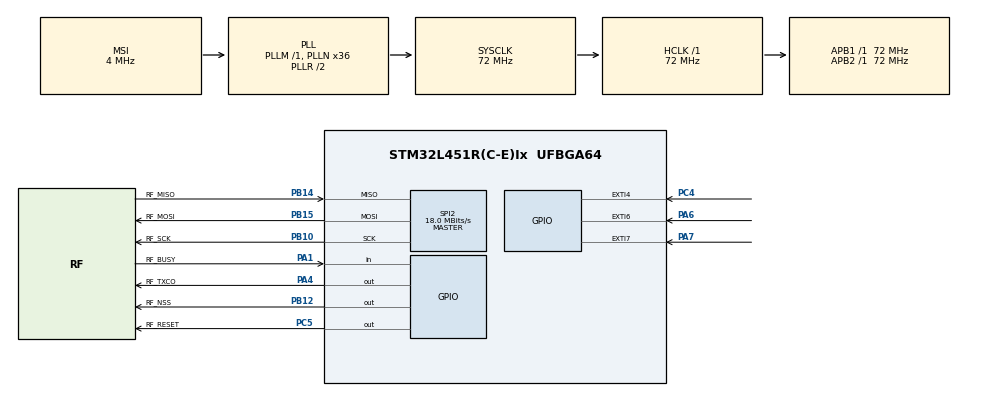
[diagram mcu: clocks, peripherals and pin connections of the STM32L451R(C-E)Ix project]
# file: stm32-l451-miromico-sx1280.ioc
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Mcu.Family=STM32L4
Dma.SPI2_RX.0.Instance=DMA1_Channel4
TIM2.Channel-Output\ Compare1\ No\ Output=TIM_CHANNEL_1
RCC.CortexFreq_Value=72000000
NVIC.DMA1_Channel5_IRQn=true\:0\:0\:false\:false\:true\:false\:true
SPI2.VirtualType=VM_MASTER
PB10.Mode=Full_Duplex_Master
PB14.GPIO_Label=RF_MISO
Dma.SPI2_TX.1.PeriphInc=DMA_PINC_DISABLE
PC15-OSC32_OUT\ (PC15).Mode=LSE-External-Oscillator
PB15.Signal=SPI2_MOSI
RCC.SYSCLKSource=RCC_SYSCLKSOURCE_PLLCLK
ProjectManager.StackSize=0x400
PC14-OSC32_IN\ (PC14).Mode=LSE-External-Oscillator
RCC.HCLKFreq_Value=72000000
RCC.APB2TimFreq_Value=72000000
RCC.AHBFreq_Value=72000000
SPI2.BaudRatePrescaler=SPI_BAUDRATEPRESCALER_4
RCC.HSE_VALUE=8000000
VP_TIM2_VS_no_output1.Mode=Output Compare1 No Output
PB12.GPIO_Label=RF_NSS
PB14.Mode=Full_Duplex_Master
NVIC.TIM2_IRQn=true\:0\:0\:false\:false\:true\:true\:true
SPI2.CalculateBaudRate=18.0 MBits/s
Dma.SPI2_RX.0.MemDataAlignment=DMA_MDATAALIGN_BYTE
NVIC.SPI2_IRQn=true\:0\:0\:false\:false\:true\:true\:true
Dma.SPI2_RX.0.MemInc=DMA_MINC_ENABLE
Mcu.Package=UFBGA64
TIM2.Prescaler=71
PA6.Signal=GPXTI6
Dma.SPI2_TX.1.Mode=DMA_NORMAL
SPI2.Mode=SPI_MODE_MASTER
VP_LPTIM1_VS_LPTIM_counterModeInternalClock.Mode=Counts__internal_clock_event_00
Dma.SPI2_TX.1.Instance=DMA1_Channel5
Dma.Request1=SPI2_TX
RCC.APB1TimFreq_Value=72000000
SPI2.Direction=SPI_DIRECTION_2LINES
PC5.Signal=GPIO_Output
Dma.SPI2_RX.0.Direction=DMA_PERIPH_TO_MEMORY
NVIC.DMA1_Channel4_IRQn=true\:0\:0\:false\:false\:true\:false\:true
Dma.Request0=SPI2_RX
PA4.GPIO_Label=RF_TXCO
RCC.HSI48_VALUE=48000000
RCC.MSI_VALUE=4000000
Dma.SPI2_TX.1.MemInc=DMA_MINC_ENABLE
NVIC.EXTI4_IRQn=true\:0\:0\:false\:false\:true\:true\:true
Dma.SPI2_RX.0.Mode=DMA_NORMAL
PC4.Signal=GPXTI4
PC15-OSC32_OUT\ (PC15).Signal=RCC_OSC32_OUT
Dma.SPI2_RX.0.PeriphDataAlignment=DMA_PDATAALIGN_BYTE
ProjectManager.TargetToolchain=Makefile
PB10.GPIO_Label=RF_SCK
RCC.LPTIM1CLockSelection=RCC_LPTIM1CLKSOURCE_LSE
PA1.Signal=GPIO_Input
PB12.GPIO_Speed=GPIO_SPEED_FREQ_VERY_HIGH
PB10.Signal=SPI2_SCK
PB14.Signal=SPI2_MISO
board=custom
Dma.SPI2_TX.1.Direction=DMA_MEMORY_TO_PERIPH
RCC.VCOOutputFreq_Value=144000000
PB15.Mode=Full_Duplex_Master
NVIC.LPTIM1_IRQn=true\:0\:0\:false\:false\:true\:true\:true
RCC.APB2Freq_Value=72000000
Dma.SPI2_TX.1.PeriphDataAlignment=DMA_PDATAALIGN_BYTE
PB15.GPIO_Label=RF_MOSI
VP_TIM2_VS_ClockSourceINT.Mode=Internal
Dma.SPI2_TX.1.Priority=DMA_PRIORITY_LOW
RCC.ADCFreq_Value=16000000
PA1.GPIO_Label=RF_BUSY
TIM2.Period=0xffffffff
Dma.SPI2_RX.0.Priority=DMA_PRIORITY_LOW
Mcu.Name=STM32L451R(C-E)Ix
PA4.Signal=GPIO_Output
RCC.SYSCLKFreq_VALUE=72000000
PC5.GPIO_Label=RF_RESET
PC14-OSC32_IN\ (PC14).Signal=RCC_OSC32_IN
Dma.SPI2_RX.0.PeriphInc=DMA_PINC_DISABLE
NVIC.EXTI9_5_IRQn=true\:0\:0\:false\:false\:true\:true\:true
ProjectManager.HeapSize=0x200
RCC.HSI_VALUE=16000000
NVIC.PriorityGroup=NVIC_PRIORITYGROUP_4
RCC.PLLN=36
SPI2.DataSize=SPI_DATASIZE_8BIT
RCC.APB1Freq_Value=72000000
Dma.SPI2_TX.1.MemDataAlignment=DMA_MDATAALIGN_BYTE
PB12.Signal=GPIO_Output
PA7.Signal=GPXTI7

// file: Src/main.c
/* USER CODE BEGIN Header */
/**
  ******************************************************************************
  * @file           : main.c
  * @brief          : Main program body
  ******************************************************************************
  * @attention
  *
  * <h2><center>&copy; Copyright (c) 2020 STMicroelectronics.
  * All rights reserved.</center></h2>
  *
  * This software component is licensed by ST under BSD 3-Clause license,
  * the "License"; You may not use this file except in compliance with the
  * License. You may obtain a copy of the License at:
  *                        opensource.org/licenses/BSD-3-Clause
  *
  ******************************************************************************
  */
/* USER CODE END Header */

#include "main.h"

/* USER CODE BEGIN Includes */
#include "SEGGER_RTT.h"
#include <stdio.h>
#include "sx1280-hal.h"

/* USER CODE END Includes */

/* USER CODE BEGIN PM */
#define printf(format, ...) SEGGER_RTT_printf(0, format,  ## __VA_ARGS__)

/* USER CODE END PM */

LPTIM_HandleTypeDef hlptim1;

SPI_HandleTypeDef hspi2;
DMA_HandleTypeDef hdma_spi2_rx;
DMA_HandleTypeDef hdma_spi2_tx;

TIM_HandleTypeDef htim2;

void SystemClock_Config(void);
static void MX_GPIO_Init(void);
static void MX_DMA_Init(void);
static void MX_SPI2_Init(void);
static void MX_TIM2_Init(void);
static void MX_LPTIM1_Init(void);
/* USER CODE BEGIN PFP */
void btstack_port(void);

/* USER CODE END PFP */

int main(void)
{

  /* MCU Configuration--------------------------------------------------------*/

  /* Reset of all peripherals, Initializes the Flash interface and the Systick. */
  HAL_Init();

  /* Configure the system clock */
  SystemClock_Config();

  /* Initialize all configured peripherals */
  MX_GPIO_Init();
  MX_DMA_Init();
  MX_SPI2_Init();
  MX_TIM2_Init();
  MX_LPTIM1_Init();
  /* USER CODE BEGIN 2 */

  HAL_TIM_Base_Start(&htim2);
  // HAL_LPTIM_Counter_Start_IT same as HAL_LPTIM_Counter_Start but also enables IRQs
  HAL_LPTIM_Counter_Start_IT(&hlptim1, 0xffff);

  // Enable SX1280 Clock
  HAL_GPIO_WritePin(RF_TXCO_GPIO_Port, RF_TXCO_Pin, GPIO_PIN_SET);

  btstack_port();

  /* USER CODE END 2 */

  /* Infinite loop */
  /* USER CODE BEGIN WHILE */
  while (1)
  {
    // printf("[%06u] BUSY %u\n", hal_time_ms(), HAL_GPIO_ReadPin(RF_BUSY_GPIO_Port, RF_BUSY_Pin));
    /* USER CODE END WHILE */

  }
}

void SystemClock_Config(void)
{
  RCC_OscInitTypeDef RCC_OscInitStruct = {0};
  RCC_ClkInitTypeDef RCC_ClkInitStruct = {0};
  RCC_PeriphCLKInitTypeDef PeriphClkInit = {0};

  /** Configure LSE Drive Capability
  */
  HAL_PWR_EnableBkUpAccess();
  __HAL_RCC_LSEDRIVE_CONFIG(RCC_LSEDRIVE_LOW);
  /** Initializes the CPU, AHB and APB busses clocks
  */
  RCC_OscInitStruct.OscillatorType = RCC_OSCILLATORTYPE_LSE|RCC_OSCILLATORTYPE_MSI;
  RCC_OscInitStruct.LSEState = RCC_LSE_ON;
  RCC_OscInitStruct.MSIState = RCC_MSI_ON;
  RCC_OscInitStruct.MSICalibrationValue = 0;
  RCC_OscInitStruct.MSIClockRange = RCC_MSIRANGE_6;
  RCC_OscInitStruct.PLL.PLLState = RCC_PLL_ON;
  RCC_OscInitStruct.PLL.PLLSource = RCC_PLLSOURCE_MSI;
  RCC_OscInitStruct.PLL.PLLM = 1;
  RCC_OscInitStruct.PLL.PLLN = 36;
  RCC_OscInitStruct.PLL.PLLP = RCC_PLLP_DIV7;
  RCC_OscInitStruct.PLL.PLLQ = RCC_PLLQ_DIV2;
  RCC_OscInitStruct.PLL.PLLR = RCC_PLLR_DIV2;
  if (HAL_RCC_OscConfig(&RCC_OscInitStruct) != HAL_OK)
  {
    Error_Handler();
  }
  /** Initializes the CPU, AHB and APB busses clocks
  */
  RCC_ClkInitStruct.ClockType = RCC_CLOCKTYPE_HCLK|RCC_CLOCKTYPE_SYSCLK
                              |RCC_CLOCKTYPE_PCLK1|RCC_CLOCKTYPE_PCLK2;
  RCC_ClkInitStruct.SYSCLKSource = RCC_SYSCLKSOURCE_PLLCLK;
  RCC_ClkInitStruct.AHBCLKDivider = RCC_SYSCLK_DIV1;
  RCC_ClkInitStruct.APB1CLKDivider = RCC_HCLK_DIV1;
  RCC_ClkInitStruct.APB2CLKDivider = RCC_HCLK_DIV1;

  if (HAL_RCC_ClockConfig(&RCC_ClkInitStruct, FLASH_LATENCY_4) != HAL_OK)
  {
    Error_Handler();
  }
  PeriphClkInit.PeriphClockSelection = RCC_PERIPHCLK_LPTIM1;
  PeriphClkInit.Lptim1ClockSelection = RCC_LPTIM1CLKSOURCE_LSE;
  if (HAL_RCCEx_PeriphCLKConfig(&PeriphClkInit) != HAL_OK)
  {
    Error_Handler();
  }
  /** Configure the main internal regulator output voltage
  */
  if (HAL_PWREx_ControlVoltageScaling(PWR_REGULATOR_VOLTAGE_SCALE1) != HAL_OK)
  {
    Error_Handler();
  }
  /** Enable MSI Auto calibration
  */
  HAL_RCCEx_EnableMSIPLLMode();
}

static void MX_LPTIM1_Init(void)
{

  hlptim1.Instance = LPTIM1;
  hlptim1.Init.Clock.Source = LPTIM_CLOCKSOURCE_APBCLOCK_LPOSC;
  hlptim1.Init.Clock.Prescaler = LPTIM_PRESCALER_DIV1;
  hlptim1.Init.Trigger.Source = LPTIM_TRIGSOURCE_SOFTWARE;
  hlptim1.Init.OutputPolarity = LPTIM_OUTPUTPOLARITY_HIGH;
  hlptim1.Init.UpdateMode = LPTIM_UPDATE_IMMEDIATE;
  hlptim1.Init.CounterSource = LPTIM_COUNTERSOURCE_INTERNAL;
  hlptim1.Init.Input1Source = LPTIM_INPUT1SOURCE_GPIO;
  hlptim1.Init.Input2Source = LPTIM_INPUT2SOURCE_GPIO;
  if (HAL_LPTIM_Init(&hlptim1) != HAL_OK)
  {
    Error_Handler();
  }

}

static void MX_SPI2_Init(void)
{

  /* SPI2 parameter configuration*/
  hspi2.Instance = SPI2;
  hspi2.Init.Mode = SPI_MODE_MASTER;
  hspi2.Init.Direction = SPI_DIRECTION_2LINES;
  hspi2.Init.DataSize = SPI_DATASIZE_8BIT;
  hspi2.Init.CLKPolarity = SPI_POLARITY_LOW;
  hspi2.Init.CLKPhase = SPI_PHASE_1EDGE;
  hspi2.Init.NSS = SPI_NSS_SOFT;
  hspi2.Init.BaudRatePrescaler = SPI_BAUDRATEPRESCALER_4;
  hspi2.Init.FirstBit = SPI_FIRSTBIT_MSB;
  hspi2.Init.TIMode = SPI_TIMODE_DISABLE;
  hspi2.Init.CRCCalculation = SPI_CRCCALCULATION_DISABLE;
  hspi2.Init.CRCPolynomial = 7;
  hspi2.Init.CRCLength = SPI_CRC_LENGTH_DATASIZE;
  hspi2.Init.NSSPMode = SPI_NSS_PULSE_ENABLE;
  if (HAL_SPI_Init(&hspi2) != HAL_OK)
  {
    Error_Handler();
  }

}

static void MX_TIM2_Init(void)
{

  TIM_ClockConfigTypeDef sClockSourceConfig = {0};
  TIM_MasterConfigTypeDef sMasterConfig = {0};
  TIM_OC_InitTypeDef sConfigOC = {0};

  htim2.Instance = TIM2;
  htim2.Init.Prescaler = 70;
  htim2.Init.CounterMode = TIM_COUNTERMODE_UP;
  htim2.Init.Period = 0xffffffff;
  htim2.Init.ClockDivision = TIM_CLOCKDIVISION_DIV1;
  htim2.Init.AutoReloadPreload = TIM_AUTORELOAD_PRELOAD_DISABLE;
  if (HAL_TIM_Base_Init(&htim2) != HAL_OK)
  {
    Error_Handler();
  }
  sClockSourceConfig.ClockSource = TIM_CLOCKSOURCE_INTERNAL;
  if (HAL_TIM_ConfigClockSource(&htim2, &sClockSourceConfig) != HAL_OK)
  {
    Error_Handler();
  }
  if (HAL_TIM_OC_Init(&htim2) != HAL_OK)
  {
    Error_Handler();
  }
  sMasterConfig.MasterOutputTrigger = TIM_TRGO_RESET;
  sMasterConfig.MasterSlaveMode = TIM_MASTERSLAVEMODE_DISABLE;
  if (HAL_TIMEx_MasterConfigSynchronization(&htim2, &sMasterConfig) != HAL_OK)
  {
    Error_Handler();
  }
  sConfigOC.OCMode = TIM_OCMODE_TIMING;
  sConfigOC.Pulse = 0;
  sConfigOC.OCPolarity = TIM_OCPOLARITY_HIGH;
  sConfigOC.OCFastMode = TIM_OCFAST_DISABLE;
  if (HAL_TIM_OC_ConfigChannel(&htim2, &sConfigOC, TIM_CHANNEL_1) != HAL_OK)
  {
    Error_Handler();
  }

}

static void MX_DMA_Init(void)
{

  /* DMA controller clock enable */
  __HAL_RCC_DMA1_CLK_ENABLE();

  /* DMA interrupt init */
  /* DMA1_Channel4_IRQn interrupt configuration */
  HAL_NVIC_SetPriority(DMA1_Channel4_IRQn, 0, 0);
  HAL_NVIC_EnableIRQ(DMA1_Channel4_IRQn);
  /* DMA1_Channel5_IRQn interrupt configuration */
  HAL_NVIC_SetPriority(DMA1_Channel5_IRQn, 0, 0);
  HAL_NVIC_EnableIRQ(DMA1_Channel5_IRQn);

}

static void MX_GPIO_Init(void)
{
  GPIO_InitTypeDef GPIO_InitStruct = {0};

  /* GPIO Ports Clock Enable */
  __HAL_RCC_GPIOC_CLK_ENABLE();
  __HAL_RCC_GPIOB_CLK_ENABLE();
  __HAL_RCC_GPIOA_CLK_ENABLE();

  /*Configure GPIO pin Output Level */
  HAL_GPIO_WritePin(RF_TXCO_GPIO_Port, RF_TXCO_Pin, GPIO_PIN_RESET);

  /*Configure GPIO pin Output Level */
  HAL_GPIO_WritePin(RF_RESET_GPIO_Port, RF_RESET_Pin, GPIO_PIN_RESET);

  /*Configure GPIO pin Output Level */
  HAL_GPIO_WritePin(RF_NSS_GPIO_Port, RF_NSS_Pin, GPIO_PIN_RESET);

  /*Configure GPIO pins : PA6 PA7 */
  GPIO_InitStruct.Pin = GPIO_PIN_6|GPIO_PIN_7;
  GPIO_InitStruct.Mode = GPIO_MODE_IT_RISING;
  GPIO_InitStruct.Pull = GPIO_NOPULL;
  HAL_GPIO_Init(GPIOA, &GPIO_InitStruct);

  /*Configure GPIO pin : RF_BUSY_Pin */
  GPIO_InitStruct.Pin = RF_BUSY_Pin;
  GPIO_InitStruct.Mode = GPIO_MODE_INPUT;
  GPIO_InitStruct.Pull = GPIO_NOPULL;
  HAL_GPIO_Init(RF_BUSY_GPIO_Port, &GPIO_InitStruct);

  /*Configure GPIO pin : RF_TXCO_Pin */
  GPIO_InitStruct.Pin = RF_TXCO_Pin;
  GPIO_InitStruct.Mode = GPIO_MODE_OUTPUT_PP;
  GPIO_InitStruct.Pull = GPIO_NOPULL;
  GPIO_InitStruct.Speed = GPIO_SPEED_FREQ_LOW;
  HAL_GPIO_Init(RF_TXCO_GPIO_Port, &GPIO_InitStruct);

  /*Configure GPIO pin : PC4 */
  GPIO_InitStruct.Pin = GPIO_PIN_4;
  GPIO_InitStruct.Mode = GPIO_MODE_IT_RISING;
  GPIO_InitStruct.Pull = GPIO_NOPULL;
  HAL_GPIO_Init(GPIOC, &GPIO_InitStruct);

  /*Configure GPIO pin : RF_RESET_Pin */
  GPIO_InitStruct.Pin = RF_RESET_Pin;
  GPIO_InitStruct.Mode = GPIO_MODE_OUTPUT_PP;
  GPIO_InitStruct.Pull = GPIO_NOPULL;
  GPIO_InitStruct.Speed = GPIO_SPEED_FREQ_LOW;
  HAL_GPIO_Init(RF_RESET_GPIO_Port, &GPIO_InitStruct);

  /*Configure GPIO pin : RF_NSS_Pin */
  GPIO_InitStruct.Pin = RF_NSS_Pin;
  GPIO_InitStruct.Mode = GPIO_MODE_OUTPUT_PP;
  GPIO_InitStruct.Pull = GPIO_NOPULL;
  GPIO_InitStruct.Speed = GPIO_SPEED_FREQ_VERY_HIGH;
  HAL_GPIO_Init(RF_NSS_GPIO_Port, &GPIO_InitStruct);

  /* EXTI interrupt init*/
  HAL_NVIC_SetPriority(EXTI4_IRQn, 0, 0);
  HAL_NVIC_EnableIRQ(EXTI4_IRQn);

  HAL_NVIC_SetPriority(EXTI9_5_IRQn, 0, 0);
  HAL_NVIC_EnableIRQ(EXTI9_5_IRQn);

}

void Error_Handler(void)
{
}

/************************ (C) COPYRIGHT STMicroelectronics *****END OF FILE****/
